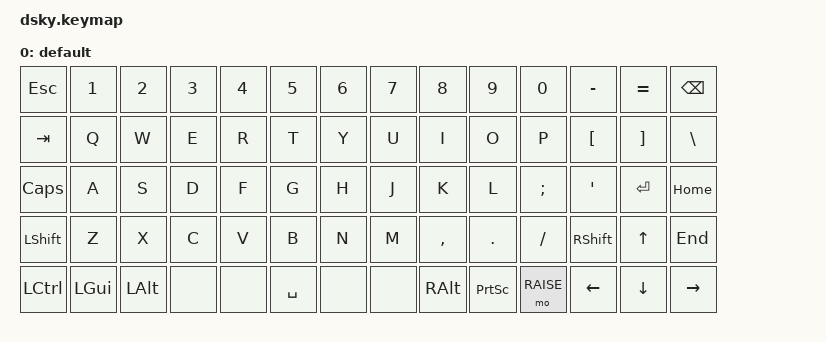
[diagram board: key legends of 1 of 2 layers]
#include <behaviors.dtsi>
#include <dt-bindings/zmk/keys.h>

#define DEFAULT 0
#define RAISE   1

/ {
    keymap {
        compatible = "zmk,keymap";
        default {
            bindings = <
                &kp ESC     &kp N1      &kp N2      &kp N3      &kp N4      &kp N5      &kp N6      &kp N7      &kp N8      &kp N9    &kp N0      &kp MINUS     &kp EQUAL   &kp BSPC
                &kp TAB     &kp Q       &kp W       &kp E       &kp R       &kp T       &kp Y       &kp U       &kp I       &kp O     &kp P       &kp LBKT      &kp RBKT    &kp BSLH
                &kp CAPS    &kp A       &kp S       &kp D       &kp F       &kp G       &kp H       &kp J       &kp K       &kp L     &kp SEMI    &kp SQT       &kp ENTER   &kp HOME
                &kp LSHFT   &kp Z       &kp X       &kp C       &kp V       &kp B       &kp N       &kp M       &kp COMMA   &kp DOT   &kp SLASH   &kp RSHIFT    &kp UP      &kp END
                &kp LCTRL   &kp LGUI    &kp LALT    &none       &none       &kp SPACE   &none       &none       &kp RALT    &kp PSCRN &mo RAISE    &kp LEFT     &kp DOWN    &kp RIGHT
            >;
        };

        raise_layer {
            display-name = "Raise Layer";
            bindings = <
                &kp GRAVE   &kp F1      &kp F2      &kp F3      &kp F4      &kp F5      &kp F6      &kp F7      &kp F8      &kp F9    &kp F10     &kp F11       &kp F12       &kp DELETE
                &trans      &trans      &trans      &trans      &trans      &trans      &trans      &trans      &trans      &trans    &trans      &trans        &trans        &trans
                &trans      &trans      &trans      &trans      &trans      &trans      &trans      &trans      &trans      &trans    &trans      &trans        &trans        &kp PG_UP
                &trans      &trans      &trans      &trans      &trans      &trans      &trans      &trans      &trans      &trans    &trans      &trans        &kp C_VOL_UP  &kp PG_DN
                &trans      &trans      &trans                              &trans                              &trans      &trans    &trans      &trans        &kp K_VOL_DN  &trans
            >;
        };
    };
};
